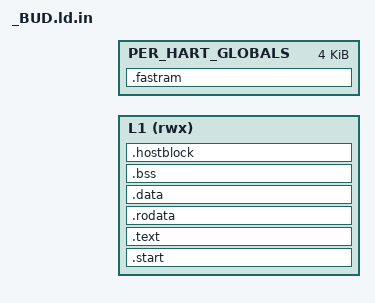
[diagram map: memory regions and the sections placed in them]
/* _BUD.ld:
  Wed Aug 27 16:11:19 2025 Spike loader script on the road to non-trivial C++ on BH
 */

#include <dev_mem_map.h>
#include "BHUMD_Constants.h"

/* Define the entry point of your program.
 * This tells the linker which symbol should be the first instruction executed. */
ENTRY(_start)

MEMORY
{
    /* Let's take half of L1 for our stuff, for now.. */
    L1 (rwx) : ORIGIN = MEM_L1_BASE, LENGTH = MEM_L1_SIZE/2

    /* we say 4K for per-hart-globals length since that's the minimum
       available and because that's all that imm12 can reach anyway.
       note for T0-T2 the stack will overlap the top of gp space */
    PER_HART_GLOBALS : ORIGIN = MEM_LOCAL_BASE, LENGTH = 4K
}

/* Define how input sections are mapped to output sections and placed in memory. */
SECTIONS
{
    /* stick fastram at the front of the private data! */
    .fastram (NOLOAD) : AT(ORIGIN(PER_HART_GLOBALS)) {
      *(.fastram)
    } > PER_HART_GLOBALS
    
    /* Set the current location counter to the start of the RAM region.
     * All subsequent sections will be placed starting from this address. */
    . = ORIGIN(L1);
    . = ALIGN(4);

    PROVIDE(__stack_top4K = ORIGIN(PER_HART_GLOBALS) + 4K);
    PROVIDE(__stack_top8K = ORIGIN(PER_HART_GLOBALS) + 8K);

    PROVIDE(__global_pointer$ = ORIGIN(PER_HART_GLOBALS) + LENGTH(PER_HART_GLOBALS)/2);

    /* .start section: Must land at 0 */
    .start :
    {
      *(.start)
    } > L1
    
    /* .text section: Contains executable code.
     * This section will be placed after the start up code in L1. */
    .text :
    {
       KEEP(*(.text.startup)) # Keep specific startup code if any
       *(.text)               # All executable code from input files
       *(.text.*)             # All executable code from input files (e.g., from templates)
     } > L1

    /* .rodata section: Contains read-only data (e.g., string literals, const variables).
     * Placed immediately after the .text section. */
    .rodata :
    {
       *(.rodata)             # Read-only data
       *(.rodata.*)
    } > L1

    /* .data section: Contains initialized global and static variables.
     * Placed immediately after the .rodata section. */
    .data :
    {
      *(.sdata)              # 'normal' initialized data
      *(.data)               # Initialized data
      *(.data.*)
    } > L1

    /* .bss section: Contains uninitialized global and static variables.
     * These variables are typically zero-initialized by startup code.
     * Placed immediately after the .data section. */
    .bss :
    {
      . = ALIGN(4);
      PROVIDE(__bss_start = .);
      *(.sbss)               # 'normal' uninitialized data? wth?
      *(.bss)                # Uninitialized data
      *(.bss.*)
      *(COMMON)              # Common symbols (uninitialized data)
      . = ALIGN(4);
      PROVIDE(__bss_end = .);
    } > L1

    .hostblock :
    {
      . = ALIGN(16);
      PROVIDE(__host_block_start = .);
      *(.hostblock)
      PROVIDE(__host_block_end = .);
      __host_block_size = __host_block_end - __host_block_start;
      PROVIDE(_end = .);
    } > L1
 }
 
